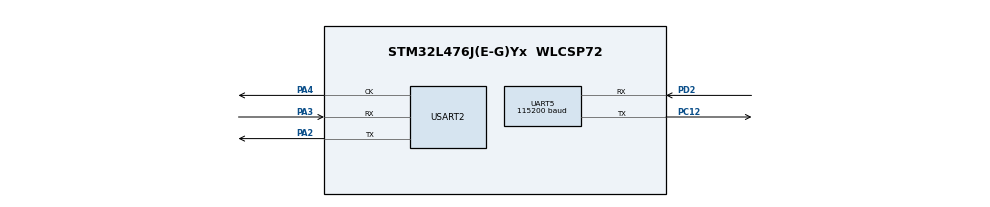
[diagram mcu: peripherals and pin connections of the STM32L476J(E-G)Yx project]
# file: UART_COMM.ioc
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Mcu.Family=STM32L4
Mcu.Name=STM32L476J(E-G)Yx
Mcu.Package=WLCSP72
NVIC.PriorityGroup=NVIC_PRIORITYGROUP_4
NVIC.UART5_IRQn=true\:0\:0\:false\:false\:true\:true\:true
PA13\ (JTMS-SWDIO).Signal=SYS_JTMS-SWDIO
PA14\ (JTCK-SWCLK).Signal=SYS_JTCK-SWCLK
PA2.Mode=Synchronous
PA2.Signal=USART2_TX
PA3.Mode=Synchronous
PA3.Signal=USART2_RX
PA4.Mode=Synchronous
PA4.Signal=USART2_CK
PC12.Mode=Asynchronous
PC12.Signal=UART5_TX
PD2.Mode=Asynchronous
PD2.Signal=UART5_RX
ProjectManager.HeapSize=0x200
ProjectManager.StackSize=0x400
ProjectManager.TargetToolchain=STM32CubeIDE
RCC.HSE_VALUE=8000000
RCC.HSI_VALUE=16000000
RCC.LSE_VALUE=32768
RCC.MSI_VALUE=4000000
RCC.VCOOutputFreq_Value=32000000
UART5.BaudRate=115200
USART2.VirtualMode-Synchronous=VM_SYNC
board=custom

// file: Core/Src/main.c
/* USER CODE BEGIN Header */
/**
  ******************************************************************************
  * @file           : main.c
  * @brief          : Main program body
  ******************************************************************************
  * @attention
  *
  * <h2><center>&copy; Copyright (c) 2021 STMicroelectronics.
  * All rights reserved.</center></h2>
  *
  * This software component is licensed by ST under BSD 3-Clause license,
  * the "License"; You may not use this file except in compliance with the
  * License. You may obtain a copy of the License at:
  *                        opensource.org/licenses/BSD-3-Clause
  *
  ******************************************************************************
  */
/* USER CODE END Header */
#include "main.h"
#include "SensorTile.h"
#include "SensorTile.c"

UART_HandleTypeDef huart5;
USART_HandleTypeDef husart2;

void SystemClock_Config(void);
static void MX_GPIO_Init(void);
static void MX_UART5_Init(void);
static void MX_USART2_Init(void);
static void Error_Handler_1(void);

/* USER CODE BEGIN 0 */
/* Buffer used for transmission */
uint8_t aTxBuffer[] = "Hello World this message will be send over and over\r\n";
/* Buffer used for reception */
uint8_t aRxBuffer[RXBUFFERSIZE];
/* USER CODE END 0 */

int main(void)
{

  /* MCU Configuration--------------------------------------------------------*/

  /* Reset of all peripherals, Initializes the Flash interface and the Systick. */
  HAL_Init();

  /* Configure the system clock */
  SystemClock_Config();

  /* Initialize all configured peripherals */
  MX_GPIO_Init();
  MX_UART5_Init();
  MX_USART2_Init();
  /* USER CODE BEGIN 2 */

	BSP_LED_Init(LED1);
	BSP_LED_On(LED1);

  while(1)
  {
		  HAL_UART_Transmit(&huart5,(uint8_t *)aTxBuffer, TXBUFFERSIZE,5);
		  if (HAL_UART_Transmit(&huart5, (uint8_t *)aTxBuffer, TXBUFFERSIZE,5) != HAL_OK)
		  {
				/* Transfer error in transmission process */
				Error_Handler_1();
		  }
		  HAL_Delay(1000);
  }
  /* USER CODE END 2 */

  /* Infinite loop */
  while (1)
  {

  }
}

static void Error_Handler_1(void)
{
	BSP_LED_Off(LED1);
	HAL_Delay(400);
	BSP_LED_On(LED1);
	HAL_Delay(400);
	BSP_LED_Off(LED1);
	HAL_Delay(400);
	BSP_LED_On(LED1);
	HAL_Delay(400);
	BSP_LED_Off(LED1);
	HAL_Delay(400);
	BSP_LED_On(LED1);
	HAL_Delay(400);
}

void SystemClock_Config(void)
{
  RCC_OscInitTypeDef RCC_OscInitStruct = {0};
  RCC_ClkInitTypeDef RCC_ClkInitStruct = {0};

  /** Configure the main internal regulator output voltage
  */
  if (HAL_PWREx_ControlVoltageScaling(PWR_REGULATOR_VOLTAGE_SCALE1) != HAL_OK)
  {
    Error_Handler();
  }
  /** Initializes the RCC Oscillators according to the specified parameters
  * in the RCC_OscInitTypeDef structure.
  */
  RCC_OscInitStruct.OscillatorType = RCC_OSCILLATORTYPE_MSI;
  RCC_OscInitStruct.MSIState = RCC_MSI_ON;
  RCC_OscInitStruct.MSICalibrationValue = 0;
  RCC_OscInitStruct.MSIClockRange = RCC_MSIRANGE_6;
  RCC_OscInitStruct.PLL.PLLState = RCC_PLL_NONE;
  if (HAL_RCC_OscConfig(&RCC_OscInitStruct) != HAL_OK)
  {
    Error_Handler();
  }
  /** Initializes the CPU, AHB and APB buses clocks
  */
  RCC_ClkInitStruct.ClockType = RCC_CLOCKTYPE_HCLK|RCC_CLOCKTYPE_SYSCLK
                              |RCC_CLOCKTYPE_PCLK1|RCC_CLOCKTYPE_PCLK2;
  RCC_ClkInitStruct.SYSCLKSource = RCC_SYSCLKSOURCE_MSI;
  RCC_ClkInitStruct.AHBCLKDivider = RCC_SYSCLK_DIV1;
  RCC_ClkInitStruct.APB1CLKDivider = RCC_HCLK_DIV1;
  RCC_ClkInitStruct.APB2CLKDivider = RCC_HCLK_DIV1;

  if (HAL_RCC_ClockConfig(&RCC_ClkInitStruct, FLASH_LATENCY_0) != HAL_OK)
  {
    Error_Handler();
  }
}

static void MX_UART5_Init(void)
{

  huart5.Instance = UART5;
  huart5.Init.BaudRate = 115200;
  huart5.Init.WordLength = UART_WORDLENGTH_8B;
  huart5.Init.StopBits = UART_STOPBITS_1;
  huart5.Init.Parity = UART_PARITY_NONE;
  huart5.Init.Mode = UART_MODE_TX_RX;
  huart5.Init.HwFlowCtl = UART_HWCONTROL_NONE;
  huart5.Init.OverSampling = UART_OVERSAMPLING_16;
  huart5.Init.OneBitSampling = UART_ONE_BIT_SAMPLE_DISABLE;
  huart5.AdvancedInit.AdvFeatureInit = UART_ADVFEATURE_NO_INIT;
  if (HAL_UART_Init(&huart5) != HAL_OK)
  {
    Error_Handler();
  }

}

static void MX_USART2_Init(void)
{

  husart2.Instance = USART2;
  husart2.Init.BaudRate = 115200;
  husart2.Init.WordLength = USART_WORDLENGTH_8B;
  husart2.Init.StopBits = USART_STOPBITS_1;
  husart2.Init.Parity = USART_PARITY_NONE;
  husart2.Init.Mode = USART_MODE_TX_RX;
  husart2.Init.CLKPolarity = USART_POLARITY_LOW;
  husart2.Init.CLKPhase = USART_PHASE_1EDGE;
  husart2.Init.CLKLastBit = USART_LASTBIT_DISABLE;
  if (HAL_USART_Init(&husart2) != HAL_OK)
  {
    Error_Handler();
  }

}

static void MX_GPIO_Init(void)
{

  /* GPIO Ports Clock Enable */
  __HAL_RCC_GPIOD_CLK_ENABLE();
  __HAL_RCC_GPIOA_CLK_ENABLE();
  __HAL_RCC_GPIOC_CLK_ENABLE();

}

void Error_Handler(void)
{
  __disable_irq();
  while (1)
  {
  }
}

/************************ (C) COPYRIGHT STMicroelectronics *****END OF FILE****/
